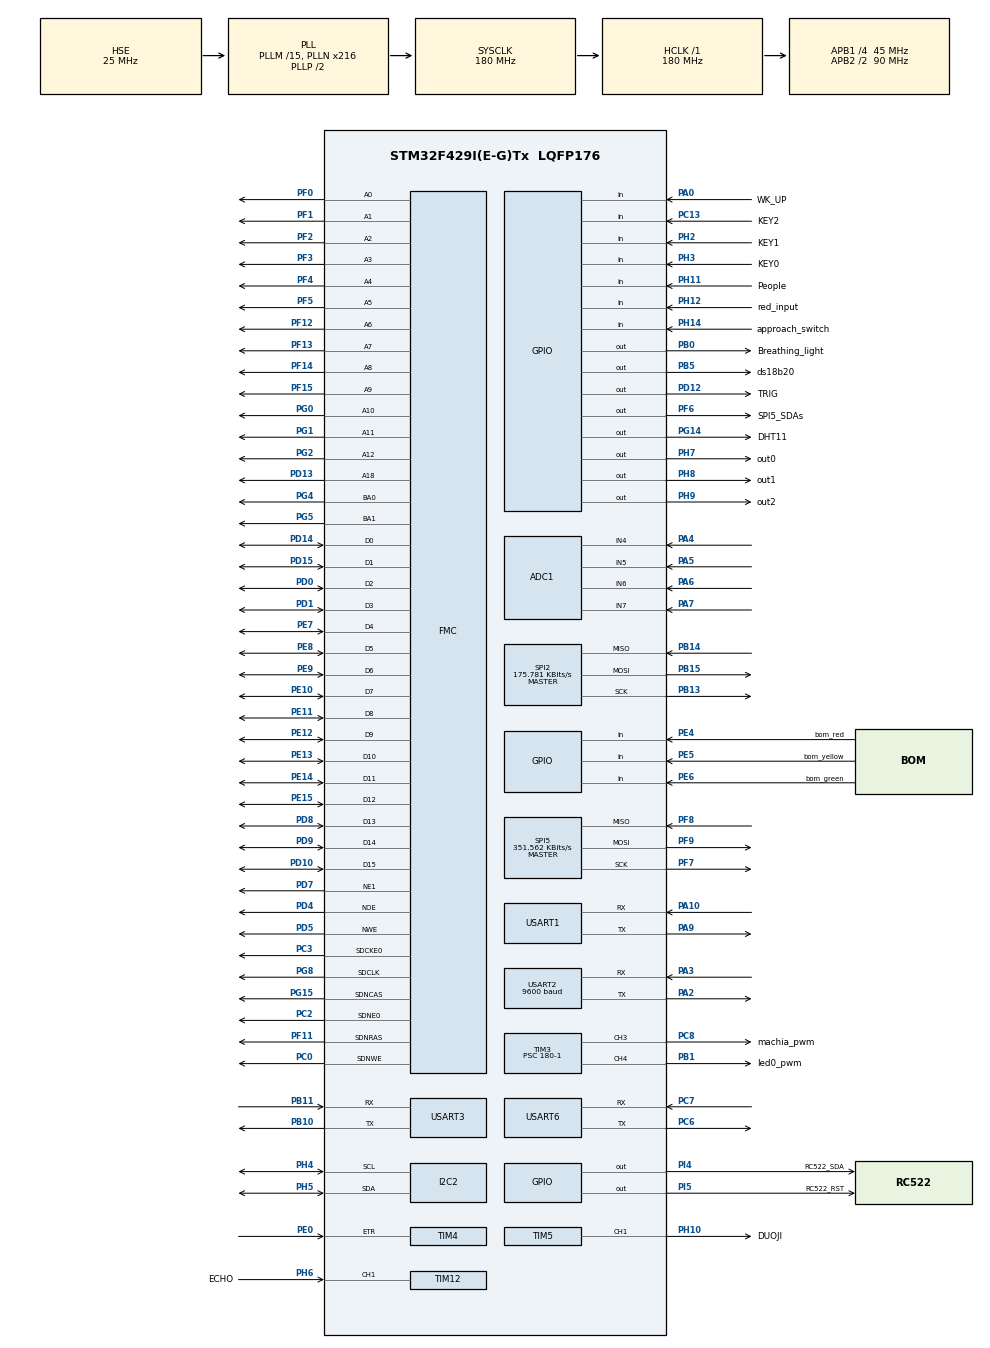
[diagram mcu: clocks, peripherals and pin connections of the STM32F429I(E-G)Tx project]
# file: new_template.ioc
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ADC1.Channel-0\#ChannelRegularConversion=ADC_CHANNEL_4
ADC1.Channel-1\#ChannelRegularConversion=ADC_CHANNEL_5
ADC1.Channel-2\#ChannelRegularConversion=ADC_CHANNEL_6
ADC1.Channel-3\#ChannelRegularConversion=ADC_CHANNEL_7
ADC1.ContinuousConvMode=ENABLE
ADC1.DMAContinuousRequests=ENABLE
ADC1.NbrOfConversion=4
ADC1.NbrOfConversionFlag=1
ADC1.Rank-0\#ChannelRegularConversion=1
ADC1.Rank-1\#ChannelRegularConversion=2
ADC1.Rank-2\#ChannelRegularConversion=3
ADC1.Rank-3\#ChannelRegularConversion=4
ADC1.SamplingTime-0\#ChannelRegularConversion=ADC_SAMPLETIME_15CYCLES
ADC1.SamplingTime-1\#ChannelRegularConversion=ADC_SAMPLETIME_15CYCLES
ADC1.SamplingTime-2\#ChannelRegularConversion=ADC_SAMPLETIME_15CYCLES
ADC1.SamplingTime-3\#ChannelRegularConversion=ADC_SAMPLETIME_15CYCLES
ADC1.ScanConvMode=ENABLE
ADC1.master=1
Dma.ADC1.1.Direction=DMA_PERIPH_TO_MEMORY
Dma.ADC1.1.FIFOMode=DMA_FIFOMODE_DISABLE
Dma.ADC1.1.Instance=DMA2_Stream0
Dma.ADC1.1.MemDataAlignment=DMA_MDATAALIGN_WORD
Dma.ADC1.1.MemInc=DMA_MINC_ENABLE
Dma.ADC1.1.Mode=DMA_CIRCULAR
Dma.ADC1.1.PeriphDataAlignment=DMA_PDATAALIGN_WORD
Dma.ADC1.1.PeriphInc=DMA_PINC_DISABLE
Dma.ADC1.1.Priority=DMA_PRIORITY_HIGH
Dma.Request0=USART3_RX
Dma.Request1=ADC1
Dma.Request2=USART2_TX
Dma.Request3=USART6_TX
Dma.USART2_TX.2.Direction=DMA_MEMORY_TO_PERIPH
Dma.USART2_TX.2.FIFOMode=DMA_FIFOMODE_DISABLE
Dma.USART2_TX.2.Instance=DMA1_Stream6
Dma.USART2_TX.2.MemDataAlignment=DMA_MDATAALIGN_BYTE
Dma.USART2_TX.2.MemInc=DMA_MINC_ENABLE
Dma.USART2_TX.2.Mode=DMA_NORMAL
Dma.USART2_TX.2.PeriphDataAlignment=DMA_PDATAALIGN_BYTE
Dma.USART2_TX.2.PeriphInc=DMA_PINC_DISABLE
Dma.USART2_TX.2.Priority=DMA_PRIORITY_HIGH
Dma.USART3_RX.0.Direction=DMA_PERIPH_TO_MEMORY
Dma.USART3_RX.0.FIFOMode=DMA_FIFOMODE_DISABLE
Dma.USART3_RX.0.Instance=DMA1_Stream1
Dma.USART3_RX.0.MemDataAlignment=DMA_MDATAALIGN_BYTE
Dma.USART3_RX.0.MemInc=DMA_MINC_ENABLE
Dma.USART3_RX.0.Mode=DMA_NORMAL
Dma.USART3_RX.0.PeriphDataAlignment=DMA_PDATAALIGN_BYTE
Dma.USART3_RX.0.PeriphInc=DMA_PINC_DISABLE
Dma.USART3_RX.0.Priority=DMA_PRIORITY_LOW
Dma.USART6_TX.3.Direction=DMA_MEMORY_TO_PERIPH
Dma.USART6_TX.3.FIFOMode=DMA_FIFOMODE_DISABLE
Dma.USART6_TX.3.Instance=DMA2_Stream6
Dma.USART6_TX.3.MemDataAlignment=DMA_MDATAALIGN_BYTE
Dma.USART6_TX.3.MemInc=DMA_MINC_ENABLE
Dma.USART6_TX.3.Mode=DMA_NORMAL
Dma.USART6_TX.3.PeriphDataAlignment=DMA_PDATAALIGN_BYTE
Dma.USART6_TX.3.PeriphInc=DMA_PINC_DISABLE
Dma.USART6_TX.3.Priority=DMA_PRIORITY_HIGH
FMC.BusTurnAroundDuration1=1
FMC.CASLatency1=FMC_SDRAM_CAS_LATENCY_3
FMC.ColumnBitsNumber1=FMC_SDRAM_COLUMN_BITS_NUM_9
FMC.DataSetupTime1=46
FMC.ExitSelfRefreshDelay1=8
FMC.ExtendedBusTurnAroundDuration1=1
FMC.ExtendedDataSetupTime1=15
FMC.ExtendedMode1=FMC_EXTENDED_MODE_ENABLE
FMC.LoadToActiveDelay1=2
FMC.RCDDelay1=2
FMC.RPDelay1=2
FMC.RPDelay2=2
FMC.ReadBurst1=FMC_SDRAM_RBURST_ENABLE
FMC.ReadBurst2=FMC_SDRAM_RBURST_ENABLE
FMC.ReadPipeDelay1=FMC_SDRAM_RPIPE_DELAY_1
FMC.ReadPipeDelay2=FMC_SDRAM_RPIPE_DELAY_1
FMC.RowCycleDelay1=6
FMC.RowCycleDelay2=6
FMC.SDClockPeriod1=FMC_SDRAM_CLOCK_PERIOD_2
FMC.SDClockPeriod2=FMC_SDRAM_CLOCK_PERIOD_2
FMC.SelfRefreshTime1=6
FMC.WriteRecoveryTime1=4
FREERTOS.HEAP_NUMBER=5
FREERTOS.Tasks01=mainTask,24,2048,mainTask_entry,Default,NULL,Dynamic,NULL,NULL
FREERTOS.configTOTAL_HEAP_SIZE=30720
IWDG.Prescaler=IWDG_PRESCALER_32
Mcu.Family=STM32F4
Mcu.Name=STM32F429I(E-G)Tx
Mcu.Package=LQFP176
NVIC.DMA1_Stream1_IRQn=true\:5\:0\:false\:false\:true\:true\:false\:true\:true
NVIC.DMA1_Stream6_IRQn=true\:5\:0\:false\:false\:true\:true\:false\:true\:true
NVIC.DMA2_Stream0_IRQn=true\:5\:0\:false\:false\:true\:true\:false\:true\:true
NVIC.DMA2_Stream6_IRQn=true\:5\:0\:false\:false\:true\:true\:false\:true\:true
NVIC.PriorityGroup=NVIC_PRIORITYGROUP_4
NVIC.TIM1_UP_TIM10_IRQn=true\:6\:0\:true\:false\:true\:true\:true\:true\:true
NVIC.TIM8_BRK_TIM12_IRQn=true\:6\:0\:true\:false\:true\:true\:true\:true\:true
NVIC.TIM8_TRG_COM_TIM14_IRQn=true\:15\:0\:false\:false\:true\:false\:false\:true\:true
NVIC.TimeBase=TIM8_TRG_COM_TIM14_IRQn
NVIC.TimeBaseIP=TIM14
NVIC.USART3_IRQn=true\:5\:0\:true\:false\:true\:true\:true\:true\:true
PA0/WKUP.GPIO_Label=WK_UP
PA0/WKUP.GPIO_PuPd=GPIO_PULLDOWN
PA0/WKUP.Signal=GPIO_Input
PA10.Mode=Asynchronous
PA10.Signal=USART1_RX
PA13.Mode=Serial_Wire
PA13.Signal=SYS_JTMS-SWDIO
PA14.Mode=Serial_Wire
PA14.Signal=SYS_JTCK-SWCLK
PA2.Mode=Asynchronous
PA2.Signal=USART2_TX
PA3.Mode=Asynchronous
PA3.Signal=USART2_RX
PA4.Signal=ADCx_IN4
PA5.Signal=ADCx_IN5
PA6.Signal=ADCx_IN6
PA7.Signal=ADCx_IN7
PA9.Mode=Asynchronous
PA9.Signal=USART1_TX
PB0.GPIO_Label=Breathing_light
PB0.PinState=GPIO_PIN_SET
PB0.Signal=GPIO_Output
PB1.GPIO_Label=led0_pwm
PB1.Signal=S_TIM3_CH4
PB10.Mode=Asynchronous
PB10.Signal=USART3_TX
PB11.Mode=Asynchronous
PB11.Signal=USART3_RX
PB13.Mode=Full_Duplex_Master
PB13.Signal=SPI2_SCK
PB14.Mode=Full_Duplex_Master
PB14.Signal=SPI2_MISO
PB15.Mode=Full_Duplex_Master
PB15.Signal=SPI2_MOSI
PB5.GPIO_Label=ds18b20
PB5.Signal=GPIO_Output
PC0.Signal=FMC_SDNWE
PC13.GPIO_Label=KEY2
PC13.GPIO_PuPd=GPIO_PULLUP
PC13.Signal=GPIO_Input
PC14/OSC32_IN.Mode=LSE-External-Oscillator
PC14/OSC32_IN.Signal=RCC_OSC32_IN
PC15/OSC32_OUT.Mode=LSE-External-Oscillator
PC15/OSC32_OUT.Signal=RCC_OSC32_OUT
PC2.Mode=SdramChipSelect1_1
PC2.Signal=FMC_SDNE0
PC3.Mode=SdramChipSelect1_1
PC3.Signal=FMC_SDCKE0
PC6.Mode=Asynchronous
PC6.Signal=USART6_TX
PC7.Mode=Asynchronous
PC7.Signal=USART6_RX
PC8.GPIO_Label=machia_pwm
PC8.Signal=S_TIM3_CH3
PD0.Signal=FMC_D2_DA2
PD1.Signal=FMC_D3_DA3
PD10.Signal=FMC_D15_DA15
PD12.GPIO_Label=TRIG
PD12.Signal=GPIO_Output
PD13.Signal=FMC_A18
PD14.Signal=FMC_D0_DA0
PD15.Signal=FMC_D1_DA1
PD4.Signal=FMC_NOE
PD5.Signal=FMC_NWE
PD7.Mode=NorPsramChipSelect1_1
PD7.Signal=FMC_NE1
PD8.Signal=FMC_D13_DA13
PD9.Signal=FMC_D14_DA14
PE0.Signal=S_TIM4_ETR
PE10.Signal=FMC_D7_DA7
PE11.Signal=FMC_D8_DA8
PE12.Signal=FMC_D9_DA9
PE13.Signal=FMC_D10_DA10
PE14.Signal=FMC_D11_DA11
PE15.Signal=FMC_D12_DA12
PE4.GPIO_Label=bom_red
PE4.GPIO_PuPd=GPIO_PULLUP
PE4.Signal=GPIO_Input
PE5.GPIO_Label=bom_yellow
PE5.GPIO_PuPd=GPIO_PULLUP
PE5.Signal=GPIO_Input
PE6.GPIO_Label=bom_green
PE6.GPIO_PuPd=GPIO_PULLUP
PE6.Signal=GPIO_Input
PE7.Signal=FMC_D4_DA4
PE8.Signal=FMC_D5_DA5
PE9.Signal=FMC_D6_DA6
PF0.Signal=FMC_A0
PF1.Signal=FMC_A1
PF11.Signal=FMC_SDNRAS
PF12.Signal=FMC_A6
PF13.Signal=FMC_A7
PF14.Signal=FMC_A8
PF15.Signal=FMC_A9
PF2.Signal=FMC_A2
PF3.Signal=FMC_A3
PF4.Signal=FMC_A4
PF5.Signal=FMC_A5
PF6.GPIO_Label=SPI5_SDAs
PF6.GPIO_PuPd=GPIO_PULLUP
PF6.GPIO_Speed=GPIO_SPEED_FREQ_VERY_HIGH
PF6.PinState=GPIO_PIN_SET
PF6.Signal=GPIO_Output
PF7.Mode=Full_Duplex_Master
PF7.Signal=SPI5_SCK
PF8.Mode=Full_Duplex_Master
PF8.Signal=SPI5_MISO
PF9.Mode=Full_Duplex_Master
PF9.Signal=SPI5_MOSI
PG0.Signal=FMC_A10
PG1.Signal=FMC_A11
PG14.GPIO_Label=DHT11
PG14.Signal=GPIO_Output
PG15.Signal=FMC_SDNCAS
PG2.Signal=FMC_A12
PG4.Signal=FMC_A14_BA0
PG5.Signal=FMC_A15_BA1
PG8.Signal=FMC_SDCLK
PH0/OSC_IN.Mode=HSE-External-Oscillator
PH0/OSC_IN.Signal=RCC_OSC_IN
PH1/OSC_OUT.Mode=HSE-External-Oscillator
PH1/OSC_OUT.Signal=RCC_OSC_OUT
PH10.GPIO_Label=DUOJI
PH10.GPIO_Speed=GPIO_SPEED_FREQ_HIGH
PH10.Signal=S_TIM5_CH1
PH11.GPIO_Label=People
PH11.Signal=GPIO_Input
PH12.GPIO_Label=red_input
PH12.Signal=GPIO_Input
PH14.GPIO_Label=approach_switch
PH14.Signal=GPIO_Input
PH2.GPIO_Label=KEY1
PH2.GPIO_PuPd=GPIO_PULLUP
PH2.Signal=GPIO_Input
PH3.GPIO_Label=KEY0
PH3.GPIO_PuPd=GPIO_PULLUP
PH3.Signal=GPIO_Input
PH4.Mode=I2C
PH4.Signal=I2C2_SCL
PH5.Mode=I2C
PH5.Signal=I2C2_SDA
PH6.GPIO_Label=ECHO
PH6.Signal=S_TIM12_CH1
PH7.GPIO_Label=out0
PH7.Signal=GPIO_Output
PH8.GPIO_Label=out1
PH8.Signal=GPIO_Output
PH9.GPIO_Label=out2
PH9.Signal=GPIO_Output
PI4.GPIO_Label=RC522_SDA
PI4.Signal=GPIO_Output
PI5.GPIO_Label=RC522_RST
PI5.Signal=GPIO_Output
ProjectManager.HeapSize=0x200
ProjectManager.StackSize=0x400
ProjectManager.TargetToolchain=MDK-ARM V5.32
RCC.48MHZClocksFreq_Value=90000000
RCC.AHBFreq_Value=180000000
RCC.APB1CLKDivider=RCC_HCLK_DIV4
RCC.APB1Freq_Value=45000000
RCC.APB1TimFreq_Value=90000000
RCC.APB2CLKDivider=RCC_HCLK_DIV2
RCC.APB2Freq_Value=90000000
RCC.APB2TimFreq_Value=180000000
RCC.CortexFreq_Value=180000000
RCC.HCLKFreq_Value=180000000
RCC.HSE_VALUE=25000000
RCC.HSI_VALUE=16000000
RCC.PLLM=15
RCC.PLLN=216
RCC.PLLSourceVirtual=RCC_PLLSOURCE_HSE
RCC.SYSCLKFreq_VALUE=180000000
RCC.SYSCLKSource=RCC_SYSCLKSOURCE_PLLCLK
RCC.VCOOutputFreq_Value=360000000
SH.ADCx_IN4.0=ADC1_IN4,IN4
SH.ADCx_IN5.0=ADC1_IN5,IN5
SH.ADCx_IN6.0=ADC1_IN6,IN6
SH.ADCx_IN7.0=ADC1_IN7,IN7
SH.FMC_A0.0=FMC_A0,13b-sda1
SH.FMC_A1.0=FMC_A1,13b-sda1
SH.FMC_A10.0=FMC_A10,13b-sda1
SH.FMC_A11.0=FMC_A11,13b-sda1
SH.FMC_A12.0=FMC_A12,13b-sda1
SH.FMC_A14_BA0.0=FMC_BA0,FourSdramBanks1
SH.FMC_A15_BA1.0=FMC_BA1,FourSdramBanks1
SH.FMC_A18.0=FMC_A18,A18_1
SH.FMC_A2.0=FMC_A2,13b-sda1
SH.FMC_A3.0=FMC_A3,13b-sda1
SH.FMC_A4.0=FMC_A4,13b-sda1
SH.FMC_A5.0=FMC_A5,13b-sda1
SH.FMC_A6.0=FMC_A6,13b-sda1
SH.FMC_A7.0=FMC_A7,13b-sda1
SH.FMC_A8.0=FMC_A8,13b-sda1
SH.FMC_A9.0=FMC_A9,13b-sda1
SH.FMC_D0_DA0.0=FMC_D0,16b-d1
SH.FMC_D0_DA0.1=FMC_D0,sd-16b-d1
SH.FMC_D10_DA10.0=FMC_D10,16b-d1
SH.FMC_D10_DA10.1=FMC_D10,sd-16b-d1
SH.FMC_D11_DA11.0=FMC_D11,16b-d1
SH.FMC_D11_DA11.1=FMC_D11,sd-16b-d1
SH.FMC_D12_DA12.0=FMC_D12,16b-d1
SH.FMC_D12_DA12.1=FMC_D12,sd-16b-d1
SH.FMC_D13_DA13.0=FMC_D13,16b-d1
SH.FMC_D13_DA13.1=FMC_D13,sd-16b-d1
SH.FMC_D14_DA14.0=FMC_D14,16b-d1
SH.FMC_D14_DA14.1=FMC_D14,sd-16b-d1
SH.FMC_D15_DA15.0=FMC_D15,16b-d1
SH.FMC_D15_DA15.1=FMC_D15,sd-16b-d1
SH.FMC_D1_DA1.0=FMC_D1,16b-d1
SH.FMC_D1_DA1.1=FMC_D1,sd-16b-d1
SH.FMC_D2_DA2.0=FMC_D2,16b-d1
SH.FMC_D2_DA2.1=FMC_D2,sd-16b-d1
SH.FMC_D3_DA3.0=FMC_D3,16b-d1
SH.FMC_D3_DA3.1=FMC_D3,sd-16b-d1
SH.FMC_D4_DA4.0=FMC_D4,16b-d1
SH.FMC_D4_DA4.1=FMC_D4,sd-16b-d1
SH.FMC_D5_DA5.0=FMC_D5,16b-d1
SH.FMC_D5_DA5.1=FMC_D5,sd-16b-d1
SH.FMC_D6_DA6.0=FMC_D6,16b-d1
SH.FMC_D6_DA6.1=FMC_D6,sd-16b-d1
SH.FMC_D7_DA7.0=FMC_D7,16b-d1
SH.FMC_D7_DA7.1=FMC_D7,sd-16b-d1
SH.FMC_D8_DA8.0=FMC_D8,16b-d1
SH.FMC_D8_DA8.1=FMC_D8,sd-16b-d1
SH.FMC_D9_DA9.0=FMC_D9,16b-d1
SH.FMC_D9_DA9.1=FMC_D9,sd-16b-d1
SH.FMC_NOE.0=FMC_NOE,Lcd1
SH.FMC_NWE.0=FMC_NWE,Lcd1
SH.FMC_SDCLK.0=FMC_SDCLK,13b-sda1
SH.FMC_SDNCAS.0=FMC_SDNCAS,13b-sda1
SH.FMC_SDNRAS.0=FMC_SDNRAS,13b-sda1
SH.FMC_SDNWE.0=FMC_SDNWE,13b-sda1
SH.S_TIM12_CH1.0=TIM12_CH1,Input_Capture1_from_TI1
SH.S_TIM3_CH3.0=TIM3_CH3,PWM Generation3 CH3
SH.S_TIM3_CH4.0=TIM3_CH4,PWM Generation4 CH4
SH.S_TIM4_ETR.0=TIM4_ETR,ClockSourceETR_Mode2
SH.S_TIM5_CH1.0=TIM5_CH1,PWM Generation1 CH1
SPI2.BaudRatePrescaler=SPI_BAUDRATEPRESCALER_256
SPI2.CalculateBaudRate=175.781 KBits/s
SPI2.Direction=SPI_DIRECTION_2LINES
SPI2.Mode=SPI_MODE_MASTER
SPI2.VirtualType=VM_MASTER
SPI5.BaudRatePrescaler=SPI_BAUDRATEPRESCALER_256
SPI5.CLKPhase=SPI_PHASE_2EDGE
SPI5.CLKPolarity=SPI_POLARITY_HIGH
SPI5.CalculateBaudRate=351.562 KBits/s
SPI5.Direction=SPI_DIRECTION_2LINES
SPI5.Mode=SPI_MODE_MASTER
SPI5.VirtualType=VM_MASTER
TIM1.AutoReloadPreload=TIM_AUTORELOAD_PRELOAD_ENABLE
TIM1.Period=10000-1
TIM1.Prescaler=18000-1
TIM10.AutoReloadPreload=TIM_AUTORELOAD_PRELOAD_ENABLE
TIM10.Period=1000
TIM10.Prescaler=18000-1
TIM12.AutoReloadPreload=TIM_AUTORELOAD_PRELOAD_ENABLE
TIM12.Channel-Input_Capture1_from_TI1=TIM_CHANNEL_1
TIM12.Period=65536-1
TIM12.Prescaler=180-1
TIM3.AutoReloadPreload=TIM_AUTORELOAD_PRELOAD_ENABLE
TIM3.Channel-PWM\ Generation3\ CH3=TIM_CHANNEL_3
TIM3.Channel-PWM\ Generation4\ CH4=TIM_CHANNEL_4
TIM3.Period=500-1
TIM3.Prescaler=180-1
TIM3.Pulse-PWM\ Generation3\ CH3=499
TIM3.Pulse-PWM\ Generation4\ CH4=499
TIM5.AutoReloadPreload=TIM_AUTORELOAD_PRELOAD_ENABLE
TIM5.Channel-PWM\ Generation1\ CH1=TIM_CHANNEL_1
TIM5.Period=2000-1
TIM5.Prescaler=900-1
USART1.VirtualMode=VM_ASYNC
USART2.BaudRate=9600
USART2.VirtualMode=VM_ASYNC
USART3.VirtualMode=VM_ASYNC
USART6.VirtualMode=VM_ASYNC
VP_FREERTOS_VS_CMSIS_V2.Mode=CMSIS_V2
VP_IWDG_VS_IWDG.Mode=IWDG_Activate
VP_SYS_VS_tim14.Mode=TIM14
VP_TIM10_VS_ClockSourceINT.Mode=Enable_Timer
VP_TIM12_VS_ClockSourceINT.Mode=Internal
VP_TIM1_VS_ClockSourceINT.Mode=Internal
VP_TIM3_VS_ClockSourceINT.Mode=Internal
VP_TIM5_VS_ClockSourceINT.Mode=Internal
board=custom

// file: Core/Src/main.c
/* USER CODE BEGIN Header */
/**
  ******************************************************************************
  * @file           : main.c
  * @brief          : Main program body
  ******************************************************************************
  * @attention
  *
  * Copyright (c) 2023 STMicroelectronics.
  * All rights reserved.
  *
  * This software is licensed under terms that can be found in the LICENSE file
  * in the root directory of this software component.
  * If no LICENSE file comes with this software, it is provided AS-IS.
  *
  ******************************************************************************
  */
/* USER CODE END Header */
#include "main.h"
#include "cmsis_os.h"
#include "adc.h"
#include "dma.h"
#include "i2c.h"
#include "iwdg.h"
#include "spi.h"
#include "tim.h"
#include "usart.h"
#include "gpio.h"
#include "fmc.h"

void SystemClock_Config(void);
void MX_FREERTOS_Init(void);

/* USER CODE BEGIN 0 */
char ping_buff[64];
/* USER CODE END 0 */

int main(void)
{

  /* MCU Configuration--------------------------------------------------------*/

  /* Reset of all peripherals, Initializes the Flash interface and the Systick. */
  HAL_Init();

  /* Configure the system clock */
  SystemClock_Config();

  /* Initialize all configured peripherals */
  MX_GPIO_Init();
  MX_DMA_Init();
  MX_TIM1_Init();
  MX_USART1_UART_Init();
  MX_USART3_UART_Init();
  MX_ADC1_Init();
  MX_FMC_Init();
  MX_I2C2_Init();
  MX_SPI2_Init();
  MX_SPI5_Init();
  MX_TIM3_Init();
  MX_TIM4_Init();
  MX_TIM10_Init();
  MX_TIM12_Init();
  MX_USART2_UART_Init();
  MX_USART6_UART_Init();
//  MX_IWDG_Init();
  MX_TIM5_Init();
  /* USER CODE BEGIN 2 */

	memset(ping_buff,0,sizeof(ping_buff));
	sprintf(ping_buff,"{\"clientId\":\"%s\",\"Device_ID\":\"%s\"}",DEVID,PROID);
  /* USER CODE END 2 */

  /* Init scheduler */
  osKernelInitialize();  /* Call init function for freertos objects (in freertos.c) */
  MX_FREERTOS_Init();

  /* Start scheduler */
  osKernelStart();
  /* We should never get here as control is now taken by the scheduler */
  /* Infinite loop */
  while (1)
  {

  }
}

void SystemClock_Config(void)
{
  RCC_OscInitTypeDef RCC_OscInitStruct = {0};
  RCC_ClkInitTypeDef RCC_ClkInitStruct = {0};

  /** Configure the main internal regulator output voltage
  */
  __HAL_RCC_PWR_CLK_ENABLE();
  __HAL_PWR_VOLTAGESCALING_CONFIG(PWR_REGULATOR_VOLTAGE_SCALE1);

  /** Initializes the RCC Oscillators according to the specified parameters
  * in the RCC_OscInitTypeDef structure.
  */
  RCC_OscInitStruct.OscillatorType = RCC_OSCILLATORTYPE_LSI|RCC_OSCILLATORTYPE_HSE;
  RCC_OscInitStruct.HSEState = RCC_HSE_ON;
  RCC_OscInitStruct.LSIState = RCC_LSI_ON;
  RCC_OscInitStruct.PLL.PLLState = RCC_PLL_ON;
  RCC_OscInitStruct.PLL.PLLSource = RCC_PLLSOURCE_HSE;
  RCC_OscInitStruct.PLL.PLLM = 15;
  RCC_OscInitStruct.PLL.PLLN = 216;
  RCC_OscInitStruct.PLL.PLLP = RCC_PLLP_DIV2;
  RCC_OscInitStruct.PLL.PLLQ = 4;
  if (HAL_RCC_OscConfig(&RCC_OscInitStruct) != HAL_OK)
  {
    Error_Handler();
  }

  /** Activate the Over-Drive mode
  */
  if (HAL_PWREx_EnableOverDrive() != HAL_OK)
  {
    Error_Handler();
  }

  /** Initializes the CPU, AHB and APB buses clocks
  */
  RCC_ClkInitStruct.ClockType = RCC_CLOCKTYPE_HCLK|RCC_CLOCKTYPE_SYSCLK
                              |RCC_CLOCKTYPE_PCLK1|RCC_CLOCKTYPE_PCLK2;
  RCC_ClkInitStruct.SYSCLKSource = RCC_SYSCLKSOURCE_PLLCLK;
  RCC_ClkInitStruct.AHBCLKDivider = RCC_SYSCLK_DIV1;
  RCC_ClkInitStruct.APB1CLKDivider = RCC_HCLK_DIV4;
  RCC_ClkInitStruct.APB2CLKDivider = RCC_HCLK_DIV2;

  if (HAL_RCC_ClockConfig(&RCC_ClkInitStruct, FLASH_LATENCY_5) != HAL_OK)
  {
    Error_Handler();
  }
}

/* USER CODE BEGIN 4 */
static uint8_t beep_num = 0;
static uint16_t send_num_flag = 0;

/* USER CODE END 4 */

void HAL_TIM_PeriodElapsedCallback(TIM_HandleTypeDef *htim)
{
  /* USER CODE BEGIN Callback 0 */

	/*  定时1s  */
	if(htim->Instance == TIM1)
	{

		HAL_GPIO_TogglePin(Breathing_light_GPIO_Port,Breathing_light_Pin);
		if(time_flag)
		{
			time_set();
		}

		if(net_connect == 1)
		{
			send_num_flag++;
			/* 保活 */
			if(send_num_flag%3==0)
			{
				Send_queue(ping_buff);
			}

			/*时间同步*/
			if(((time_flag==0))&(send_num_flag%2 == 0))
			{
				OneNet_Send_Device_ID_Data();
			}

			if(send_num_flag%5==0)
			{
				OneNet_SendData(0);//发送数据给onenet
			}
			if(send_num_flag>=10){
				send_num_flag = 0;
			}
		}
		else{

#if IWDG_FLAG
			HAL_IWDG_Refresh(&hiwdg);               // 喂狗
#endif
		}

	}

	/*   定时0.1  */
	if(htim->Instance == TIM10)
	{

		if((tem_flag == 0) && (Hum_flag == 0) && (Gas_flag == 0)&&(fire_flag==0))
		{
			if(beep_num)
			{
				PCF8574_WriteBit(BEEP_IO, 1);  // 关闭
				HAL_TIM_Base_Stop_IT(&htim10);
			}
			beep_num = 0;
		}

		if(fire_flag==1)
		{
			if(beep_num == 1)
				PCF8574_WriteBit(BEEP_IO, 0);
			else if(beep_num == 2)
				PCF8574_WriteBit(BEEP_IO, 1);
			beep_num++;
			if(beep_num >= 10)
			{
				beep_num = 1;
			}

		}

		// 响0.1 秒  不响 0.9
		if(tem_flag == 1)
		{

			if(beep_num == 1)
				PCF8574_WriteBit(BEEP_IO, 0);
			else if(beep_num == 2)
				PCF8574_WriteBit(BEEP_IO, 1);
			beep_num++;
			if(beep_num >= 10)
			{
				beep_num = 1;
			}

		}

		// 响 0.9
		if(Hum_flag == 1)
		{

			if(beep_num == 1)
				PCF8574_WriteBit(BEEP_IO, 0);
			else if(beep_num == 9)
				PCF8574_WriteBit(BEEP_IO, 1);
			beep_num++;
			if(beep_num >= 10)
			{
				beep_num = 1;
			}

		}

		// 响 0.5
		if(Gas_flag == 1)
		{

			if(beep_num == 1)
				PCF8574_WriteBit(BEEP_IO, 0);
			else if(beep_num == 5)
				PCF8574_WriteBit(BEEP_IO, 1);
			beep_num++;
			if(beep_num >= 10)
			{
				beep_num = 1;
			}

		}
	}

  /* USER CODE END Callback 0 */
  if (htim->Instance == TIM14) {
    HAL_IncTick();
  }
  /* USER CODE BEGIN Callback 1 */

  /*  超声波模块  */
  if(htim->Instance == TIM12)
  {
	Hcsr04TimOverflowIsr(htim);
  }

  /* USER CODE END Callback 1 */
}

void Error_Handler(void)
{
  __disable_irq();
  while (1)
  {
  }
}

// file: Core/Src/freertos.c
/* USER CODE BEGIN Header */
/**
  ******************************************************************************
  * File Name          : freertos.c
  * Description        : Code for freertos applications
  ******************************************************************************
  * @attention
  *
  * Copyright (c) 2023 STMicroelectronics.
  * All rights reserved.
  *
  * This software is licensed under terms that can be found in the LICENSE file
  * in the root directory of this software component.
  * If no LICENSE file comes with this software, it is provided AS-IS.
  *
  ******************************************************************************
  */
/* USER CODE END Header */

#include "FreeRTOS.h"
#include "task.h"
#include "main.h"
#include "cmsis_os.h"

/* USER CODE BEGIN Includes */

#define XUNJIAN_FLAG    0    // 巡检标志位

/* USER CODE END Includes */

/* Definitions for mainTask */
osThreadId_t mainTaskHandle;
const osThreadAttr_t mainTask_attributes = {
  .name = "mainTask",
  .stack_size = 2048 * 4,
  .priority = (osPriority_t) osPriorityNormal,
};

void mainTask_entry(void *argument);

void MX_FREERTOS_Init(void); /* (MISRA C 2004 rule 8.1) */

void MX_FREERTOS_Init(void) {
  /* USER CODE BEGIN Init */
	Mx_Init();
  /* USER CODE END Init */

  /* USER CODE BEGIN RTOS_MUTEX */
  /* add mutexes, ... */

	send_mutex = xSemaphoreCreateMutex();
	reve_mutex = xSemaphoreCreateMutex();

	iic_spi_mutex = xSemaphoreCreateMutex();

  /* USER CODE END RTOS_MUTEX */

  /* USER CODE BEGIN RTOS_QUEUES */
  /* add queues, ... */

  hreve_queue = xQueueCreate(REVE_MAX_QUEUE,sizeof(char *));

  hsend_queue = xQueueCreate(SEND_MAX_QUEUE,sizeof(char *));

  /* USER CODE END RTOS_QUEUES */

  /* Create the thread(s) */
  /* creation of mainTask */
  mainTaskHandle = osThreadNew(mainTask_entry, NULL, &mainTask_attributes);

  /* USER CODE BEGIN RTOS_THREADS */
  /* add threads, ... */

#if XUNJIAN_FLAG==0

/*==========================巡检不需要=============================================*/
#if RFID_FLAG
		xTaskCreate(read_rfid_thread_entry,"rfid_id",64,NULL,4,&read_rfid_id);
		vTaskSuspend(read_rfid_id);
#endif

		/*  创建逻辑线程 */
		xTaskCreate(logical_thread_entry,"logical_id",128,NULL,9,&Logical_code_id);
		vTaskSuspend(Logical_code_id);

		/*  创建按键扫描线程 */
		xTaskCreate(key_thread_entry,"key_id",128,NULL,8,&key_scan_id);
		vTaskSuspend(key_scan_id);

#endif
			/*  创建发送线程 */
		xTaskCreate(Send_data_Entry,"send_data_id",2048,NULL,9,&send_data_id);

		/*  创建采集数据线程 */
		xTaskCreate(collect_data_thread_entry,"collect_id",256,NULL,9,&collect_data_id);
		vTaskSuspend(collect_data_id);

		/*  创建lcd显示线程 */
		xTaskCreate(lcd_show_thread_entry,"lcd_id",256,NULL,osPriorityNormal+1,&show_lcd_id);
		vTaskSuspend(show_lcd_id);

  /* USER CODE END RTOS_THREADS */

}

void mainTask_entry(void *argument)
{
  /* USER CODE BEGIN mainTask_entry */
	 uint16_t timeCount = 0;
	char *receivedStr = NULL;    // 接收缓存区接收指针
	char ping_buff[64];
	memset(ping_buff,0,sizeof(ping_buff));
	sprintf(ping_buff,"{\"clientId\":\"%s\",\"Device_ID\":\"%s\"}",DEVID,PROID);

  /* Infinite loop */
  for(;;)
  {
	  if(net_connect == 1)
	  {
// ======================================== ================================================================================
			++timeCount;
			if((timeCount%470==0))
			{
#if IWDG_FLAG
				HAL_IWDG_Refresh(&hiwdg);               // 喂狗
#endif
			}

			if ((xQueueReceive(hreve_queue, &receivedStr, 0))) {
					// 处理接收到的字符串指针
					if(receivedStr != NULL)//如果返回数据不为空
					{
						Wait_reve_mutex();
						OneNet_RevPro((uint8_t*)receivedStr);//平台返回数据检测
						Release_reve_mutex();
					}

			}
			osDelay(5);

	  }
	  else if(net_connect == 2||net_connect==3)
	  {
		  if(net_connect==2)
		  {
			resest_wifi();
		  }
		  if(net_connect==3)
		  {
			resest_server();
		  }
	  }
	  else
	  {
			printf("开始连接服务器\r\n");
			Show_Str(10, 760, 200, 32, "等待连接!!!", 32, 0);
            ESP8266_Init();					//初始化ESP8266

            printf("8266初始化成功\n");

            while(OneNet_DevLink())			//接入OneNET

			HAL_Delay(50);

            net_connect = 1;
//            HAL_ADC_Start_DMA(&hadc1, (uint32_t *)adc_value, 40);

			vTaskResume(show_lcd_id);
			vTaskResume(collect_data_id);
#if XUNJIAN_FLAG==0
#if RFID_FLAG
			vTaskResume(read_rfid_id);
#endif
			vTaskResume(Logical_code_id);
			vTaskResume(key_scan_id);
#endif
            printf("接入onenet成功");

	  }

  }
  /* USER CODE END mainTask_entry */
}
